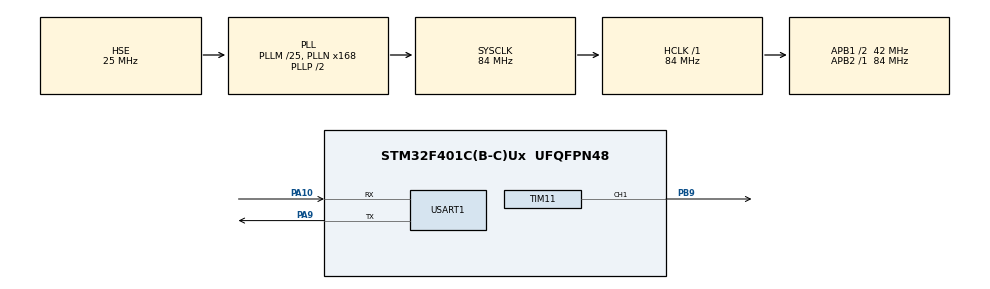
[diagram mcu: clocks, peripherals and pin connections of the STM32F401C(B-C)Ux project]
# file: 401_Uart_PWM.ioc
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Mcu.Family=STM32F4
Mcu.Name=STM32F401C(B-C)Ux
Mcu.Package=UFQFPN48
NVIC.PriorityGroup=NVIC_PRIORITYGROUP_2
NVIC.TIM1_TRG_COM_TIM11_IRQn=true\:1\:0\:true\:false\:true\:true\:true\:true
NVIC.USART1_IRQn=true\:1\:0\:true\:false\:true\:true\:true\:true
PA10.Mode=Asynchronous
PA10.Signal=USART1_RX
PA13.Mode=Serial_Wire
PA13.Signal=SYS_JTMS-SWDIO
PA14.Mode=Serial_Wire
PA14.Signal=SYS_JTCK-SWCLK
PA9.Mode=Asynchronous
PA9.Signal=USART1_TX
PB9.Signal=S_TIM11_CH1
PC14-OSC32_IN.Mode=LSE-External-Oscillator
PC14-OSC32_IN.Signal=RCC_OSC32_IN
PC15-OSC32_OUT.Mode=LSE-External-Oscillator
PC15-OSC32_OUT.Signal=RCC_OSC32_OUT
PH0\ -\ OSC_IN.Mode=HSE-External-Oscillator
PH0\ -\ OSC_IN.Signal=RCC_OSC_IN
PH1\ -\ OSC_OUT.Mode=HSE-External-Oscillator
PH1\ -\ OSC_OUT.Signal=RCC_OSC_OUT
ProjectManager.HeapSize=0x200
ProjectManager.StackSize=0x400
ProjectManager.TargetToolchain=STM32CubeIDE
RCC.48MHZClocksFreq_Value=42000000
RCC.AHBFreq_Value=84000000
RCC.APB1CLKDivider=RCC_HCLK_DIV2
RCC.APB1Freq_Value=42000000
RCC.APB1TimFreq_Value=84000000
RCC.APB2Freq_Value=84000000
RCC.APB2TimFreq_Value=84000000
RCC.CortexFreq_Value=84000000
RCC.HCLKFreq_Value=84000000
RCC.HSE_VALUE=25000000
RCC.HSI_VALUE=16000000
RCC.PLLM=25
RCC.PLLN=168
RCC.PLLSourceVirtual=RCC_PLLSOURCE_HSE
RCC.SYSCLKFreq_VALUE=84000000
RCC.SYSCLKSource=RCC_SYSCLKSOURCE_PLLCLK
RCC.VCOOutputFreq_Value=168000000
SH.S_TIM11_CH1.0=TIM11_CH1,PWM Generation1 CH1
TIM11.Channel=TIM_CHANNEL_1
TIM11.Period=200-1
TIM11.Prescaler=8400-1
TIM11.Pulse=50
USART1.VirtualMode=VM_ASYNC
VP_TIM11_VS_ClockSourceINT.Mode=Enable_Timer
board=custom

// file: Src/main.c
/* USER CODE BEGIN Header */
/**
  ******************************************************************************
  * @file           : main.c
  * @brief          : Main program body
  ******************************************************************************
  * @attention
  *
  * Copyright (c) 2022 STMicroelectronics.
  * All rights reserved.
  *
  * This software is licensed under terms that can be found in the LICENSE file
  * in the root directory of this software component.
  * If no LICENSE file comes with this software, it is provided AS-IS.
  *
  ******************************************************************************
  */
/* USER CODE END Header */
#include "main.h"
#include "tim.h"
#include "usart.h"
#include "gpio.h"

void SystemClock_Config(void);

/* USER CODE BEGIN 0 */
uint16_t prescalerWidth=8400-1;
uint16_t periodWidth=200-1;
uint16_t pulseWidth=50;

uint16_t periodWidth1;
uint16_t pulseWidth1;
/* USER CODE END 0 */

int main(void)
{

  /* MCU Configuration--------------------------------------------------------*/

  /* Reset of all peripherals, Initializes the Flash interface and the Systick. */
  HAL_Init();

  /* Configure the system clock */
  SystemClock_Config();

  /* Initialize all configured peripherals */
  MX_GPIO_Init();
  MX_TIM11_Init();
  MX_USART1_UART_Init();
  /* USER CODE BEGIN 2 */
  HAL_TIM_Base_Start_IT(&htim11);
  HAL_TIM_PWM_Start_IT(&htim11, TIM_CHANNEL_1);
  uint8_t hello1[]="hello,blocking\n";
  HAL_UART_Transmit(&huart1, hello1, sizeof(hello1), 500);
  HAL_Delay(10);
  uint8_t hello2[]="hello,none blocking\n";
  HAL_UART_Transmit_IT(&huart1, hello2, sizeof(hello2));
  HAL_UART_Receive_IT(&huart1, rxBuffer, RX_CMD_LEN);
//  __HAL_TIM_SET_AUTORELOAD(&htim11,100);

  /* USER CODE END 2 */

  /* Infinite loop */
  /* USER CODE BEGIN WHILE */
  while (1)
  {
	  periodWidth1= __HAL_TIM_GET_AUTORELOAD(&htim11);
	  pulseWidth1=__HAL_TIM_GET_COMPARE(&htim11,TIM_CHANNEL_1);
	  uint16_t ddsStr[20];
	  sprintf(ddsStr,"%2d,%2d,%2d\n",prescalerWidth,periodWidth1,pulseWidth1 );

	  if(isUploadTime){
		  HAL_UART_Transmit(&huart1, ddsStr, strlen(ddsStr), 200);
	  }
//	  __HAL_TIM_SET_COMPARE(&htim11,TIM_CHANNEL_1,pulseWidth);
//	  pulseWidth++;
	  HAL_Delay(500);

    /* USER CODE END WHILE */

  }
}

void SystemClock_Config(void)
{
  RCC_OscInitTypeDef RCC_OscInitStruct = {0};
  RCC_ClkInitTypeDef RCC_ClkInitStruct = {0};

  /** Configure the main internal regulator output voltage
  */
  __HAL_RCC_PWR_CLK_ENABLE();
  __HAL_PWR_VOLTAGESCALING_CONFIG(PWR_REGULATOR_VOLTAGE_SCALE2);

  /** Initializes the RCC Oscillators according to the specified parameters
  * in the RCC_OscInitTypeDef structure.
  */
  RCC_OscInitStruct.OscillatorType = RCC_OSCILLATORTYPE_HSE;
  RCC_OscInitStruct.HSEState = RCC_HSE_ON;
  RCC_OscInitStruct.PLL.PLLState = RCC_PLL_ON;
  RCC_OscInitStruct.PLL.PLLSource = RCC_PLLSOURCE_HSE;
  RCC_OscInitStruct.PLL.PLLM = 25;
  RCC_OscInitStruct.PLL.PLLN = 168;
  RCC_OscInitStruct.PLL.PLLP = RCC_PLLP_DIV2;
  RCC_OscInitStruct.PLL.PLLQ = 4;
  if (HAL_RCC_OscConfig(&RCC_OscInitStruct) != HAL_OK)
  {
    Error_Handler();
  }

  /** Initializes the CPU, AHB and APB buses clocks
  */
  RCC_ClkInitStruct.ClockType = RCC_CLOCKTYPE_HCLK|RCC_CLOCKTYPE_SYSCLK
                              |RCC_CLOCKTYPE_PCLK1|RCC_CLOCKTYPE_PCLK2;
  RCC_ClkInitStruct.SYSCLKSource = RCC_SYSCLKSOURCE_PLLCLK;
  RCC_ClkInitStruct.AHBCLKDivider = RCC_SYSCLK_DIV1;
  RCC_ClkInitStruct.APB1CLKDivider = RCC_HCLK_DIV2;
  RCC_ClkInitStruct.APB2CLKDivider = RCC_HCLK_DIV1;

  if (HAL_RCC_ClockConfig(&RCC_ClkInitStruct, FLASH_LATENCY_2) != HAL_OK)
  {
    Error_Handler();
  }
}

void Error_Handler(void)
{
  __disable_irq();
  while (1)
  {
  }
}
